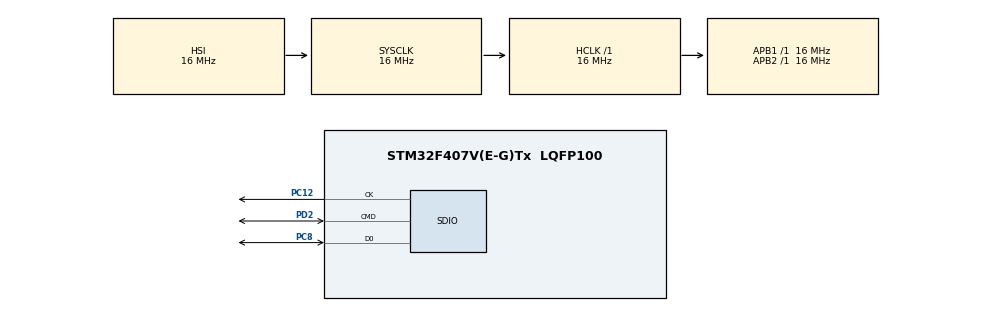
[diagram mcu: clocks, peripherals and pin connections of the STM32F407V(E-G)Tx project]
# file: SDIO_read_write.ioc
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Dma.Request0=SDIO_RX
Dma.Request1=SDIO_TX
Dma.SDIO_RX.0.Direction=DMA_PERIPH_TO_MEMORY
Dma.SDIO_RX.0.FIFOMode=DMA_FIFOMODE_ENABLE
Dma.SDIO_RX.0.FIFOThreshold=DMA_FIFO_THRESHOLD_FULL
Dma.SDIO_RX.0.Instance=DMA2_Stream3
Dma.SDIO_RX.0.MemBurst=DMA_MBURST_INC4
Dma.SDIO_RX.0.MemDataAlignment=DMA_MDATAALIGN_WORD
Dma.SDIO_RX.0.MemInc=DMA_MINC_ENABLE
Dma.SDIO_RX.0.Mode=DMA_PFCTRL
Dma.SDIO_RX.0.PeriphBurst=DMA_PBURST_INC4
Dma.SDIO_RX.0.PeriphDataAlignment=DMA_PDATAALIGN_WORD
Dma.SDIO_RX.0.PeriphInc=DMA_PINC_DISABLE
Dma.SDIO_RX.0.Priority=DMA_PRIORITY_LOW
Dma.SDIO_TX.1.Direction=DMA_MEMORY_TO_PERIPH
Dma.SDIO_TX.1.FIFOMode=DMA_FIFOMODE_ENABLE
Dma.SDIO_TX.1.FIFOThreshold=DMA_FIFO_THRESHOLD_FULL
Dma.SDIO_TX.1.Instance=DMA2_Stream6
Dma.SDIO_TX.1.MemBurst=DMA_MBURST_INC4
Dma.SDIO_TX.1.MemDataAlignment=DMA_MDATAALIGN_WORD
Dma.SDIO_TX.1.MemInc=DMA_MINC_ENABLE
Dma.SDIO_TX.1.Mode=DMA_PFCTRL
Dma.SDIO_TX.1.PeriphBurst=DMA_PBURST_INC4
Dma.SDIO_TX.1.PeriphDataAlignment=DMA_PDATAALIGN_WORD
Dma.SDIO_TX.1.PeriphInc=DMA_PINC_DISABLE
Dma.SDIO_TX.1.Priority=DMA_PRIORITY_LOW
FATFS.USE_DMA_CODE_SD=1
Mcu.Family=STM32F4
Mcu.Name=STM32F407V(E-G)Tx
Mcu.Package=LQFP100
NVIC.DMA2_Stream3_IRQn=true\:0\:0\:false\:false\:true\:false\:true\:true
NVIC.DMA2_Stream6_IRQn=true\:0\:0\:false\:false\:true\:false\:true\:true
NVIC.PriorityGroup=NVIC_PRIORITYGROUP_4
NVIC.SDIO_IRQn=true\:0\:0\:false\:false\:true\:true\:true\:true
PC12.Mode=SD_1_bit
PC12.Signal=SDIO_CK
PC8.GPIO_Mode=GPIO_MODE_AF_PP
PC8.GPIO_PuPd=GPIO_PULLUP
PC8.GPIO_Speed_High_Default=GPIO_SPEED_FREQ_VERY_HIGH
PC8.Mode=SD_1_bit
PC8.Signal=SDIO_D0
PD2.GPIO_Mode=GPIO_MODE_AF_PP
PD2.GPIO_PuPd=GPIO_PULLUP
PD2.GPIO_Speed_High_Default=GPIO_SPEED_FREQ_VERY_HIGH
PD2.Mode=SD_1_bit
PD2.Signal=SDIO_CMD
ProjectManager.HeapSize=0x200
ProjectManager.StackSize=0x400
ProjectManager.TargetToolchain=STM32CubeIDE
RCC.AHBFreq_Value=16000000
RCC.APB1Freq_Value=16000000
RCC.APB2Freq_Value=16000000
RCC.CortexFreq_Value=16000000
RCC.HSE_VALUE=25000000
RCC.HSI_VALUE=16000000
RCC.LSE_VALUE=32768
RCC.SYSCLKFreq_VALUE=16000000
RCC.VCOOutputFreq_Value=192000000
VP_FATFS_VS_SDIO.Mode=SDIO
board=custom

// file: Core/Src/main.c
/* USER CODE BEGIN Header */
/**
  ******************************************************************************
  * @file           : main.c
  * @brief          : Main program body
  ******************************************************************************
  * @attention
  *
  * Copyright (c) 2023 STMicroelectronics.
  * All rights reserved.
  *
  * This software is licensed under terms that can be found in the LICENSE file
  * in the root directory of this software component.
  * If no LICENSE file comes with this software, it is provided AS-IS.
  *
  ******************************************************************************
  */
/* USER CODE END Header */
#include "main.h"
#include "fatfs.h"

/* USER CODE BEGIN Includes */
#include "File_Handling.h"
/* USER CODE END Includes */

SD_HandleTypeDef hsd;
DMA_HandleTypeDef hdma_sdio_rx;
DMA_HandleTypeDef hdma_sdio_tx;

void SystemClock_Config(void);
static void MX_GPIO_Init(void);
static void MX_DMA_Init(void);
static void MX_SDIO_SD_Init(void);

int main(void)
{

  /* MCU Configuration--------------------------------------------------------*/

  /* Reset of all peripherals, Initializes the Flash interface and the Systick. */
  HAL_Init();

  /* Configure the system clock */
  SystemClock_Config();

  /* Initialize all configured peripherals */
  MX_GPIO_Init();
  MX_DMA_Init();
  MX_SDIO_SD_Init();
  MX_FATFS_Init();
  /* USER CODE BEGIN 2 */
	Mount_SD("/");
	Format_SD();
	Create_File("test1.TXT");
	Create_File("FILE2.TXT");
	Unmount_SD("/");
  /* USER CODE END 2 */
	Mount_SD("/");
	char buffer[] = "Hi how are you\n";
	Update_File("test1.TXT", buffer);
	Update_File("FILE2.TXT", buffer);
	Unmount_SD("/");
  /* Infinite loop */
  /* USER CODE BEGIN WHILE */
  while (1)
  {

		//HAL_Delay(2000);
    /* USER CODE END WHILE */

  }
}

void SystemClock_Config(void)
{
  RCC_OscInitTypeDef RCC_OscInitStruct = {0};
  RCC_ClkInitTypeDef RCC_ClkInitStruct = {0};

  /** Configure the main internal regulator output voltage
  */
  __HAL_RCC_PWR_CLK_ENABLE();
  __HAL_PWR_VOLTAGESCALING_CONFIG(PWR_REGULATOR_VOLTAGE_SCALE1);

  /** Initializes the RCC Oscillators according to the specified parameters
  * in the RCC_OscInitTypeDef structure.
  */
  RCC_OscInitStruct.OscillatorType = RCC_OSCILLATORTYPE_HSI;
  RCC_OscInitStruct.HSIState = RCC_HSI_ON;
  RCC_OscInitStruct.HSICalibrationValue = RCC_HSICALIBRATION_DEFAULT;
  RCC_OscInitStruct.PLL.PLLState = RCC_PLL_ON;
  RCC_OscInitStruct.PLL.PLLSource = RCC_PLLSOURCE_HSI;
  RCC_OscInitStruct.PLL.PLLM = 16;
  RCC_OscInitStruct.PLL.PLLN = 192;
  RCC_OscInitStruct.PLL.PLLP = RCC_PLLP_DIV2;
  RCC_OscInitStruct.PLL.PLLQ = 4;
  if (HAL_RCC_OscConfig(&RCC_OscInitStruct) != HAL_OK)
  {
    Error_Handler();
  }

  /** Initializes the CPU, AHB and APB buses clocks
  */
  RCC_ClkInitStruct.ClockType = RCC_CLOCKTYPE_HCLK|RCC_CLOCKTYPE_SYSCLK
                              |RCC_CLOCKTYPE_PCLK1|RCC_CLOCKTYPE_PCLK2;
  RCC_ClkInitStruct.SYSCLKSource = RCC_SYSCLKSOURCE_HSI;
  RCC_ClkInitStruct.AHBCLKDivider = RCC_SYSCLK_DIV1;
  RCC_ClkInitStruct.APB1CLKDivider = RCC_HCLK_DIV1;
  RCC_ClkInitStruct.APB2CLKDivider = RCC_HCLK_DIV1;

  if (HAL_RCC_ClockConfig(&RCC_ClkInitStruct, FLASH_LATENCY_0) != HAL_OK)
  {
    Error_Handler();
  }
}

static void MX_SDIO_SD_Init(void)
{

  hsd.Instance = SDIO;
  hsd.Init.ClockEdge = SDIO_CLOCK_EDGE_RISING;
  hsd.Init.ClockBypass = SDIO_CLOCK_BYPASS_DISABLE;
  hsd.Init.ClockPowerSave = SDIO_CLOCK_POWER_SAVE_DISABLE;
  hsd.Init.BusWide = SDIO_BUS_WIDE_1B;
  hsd.Init.HardwareFlowControl = SDIO_HARDWARE_FLOW_CONTROL_DISABLE;
  hsd.Init.ClockDiv = 0;

}

static void MX_DMA_Init(void)
{

  /* DMA controller clock enable */
  __HAL_RCC_DMA2_CLK_ENABLE();

  /* DMA interrupt init */
  /* DMA2_Stream3_IRQn interrupt configuration */
  HAL_NVIC_SetPriority(DMA2_Stream3_IRQn, 0, 0);
  HAL_NVIC_EnableIRQ(DMA2_Stream3_IRQn);
  /* DMA2_Stream6_IRQn interrupt configuration */
  HAL_NVIC_SetPriority(DMA2_Stream6_IRQn, 0, 0);
  HAL_NVIC_EnableIRQ(DMA2_Stream6_IRQn);

}

static void MX_GPIO_Init(void)
{

  /* GPIO Ports Clock Enable */
  __HAL_RCC_GPIOC_CLK_ENABLE();
  __HAL_RCC_GPIOD_CLK_ENABLE();

}

void Error_Handler(void)
{
  __disable_irq();
  while (1)
  {
  }
}
